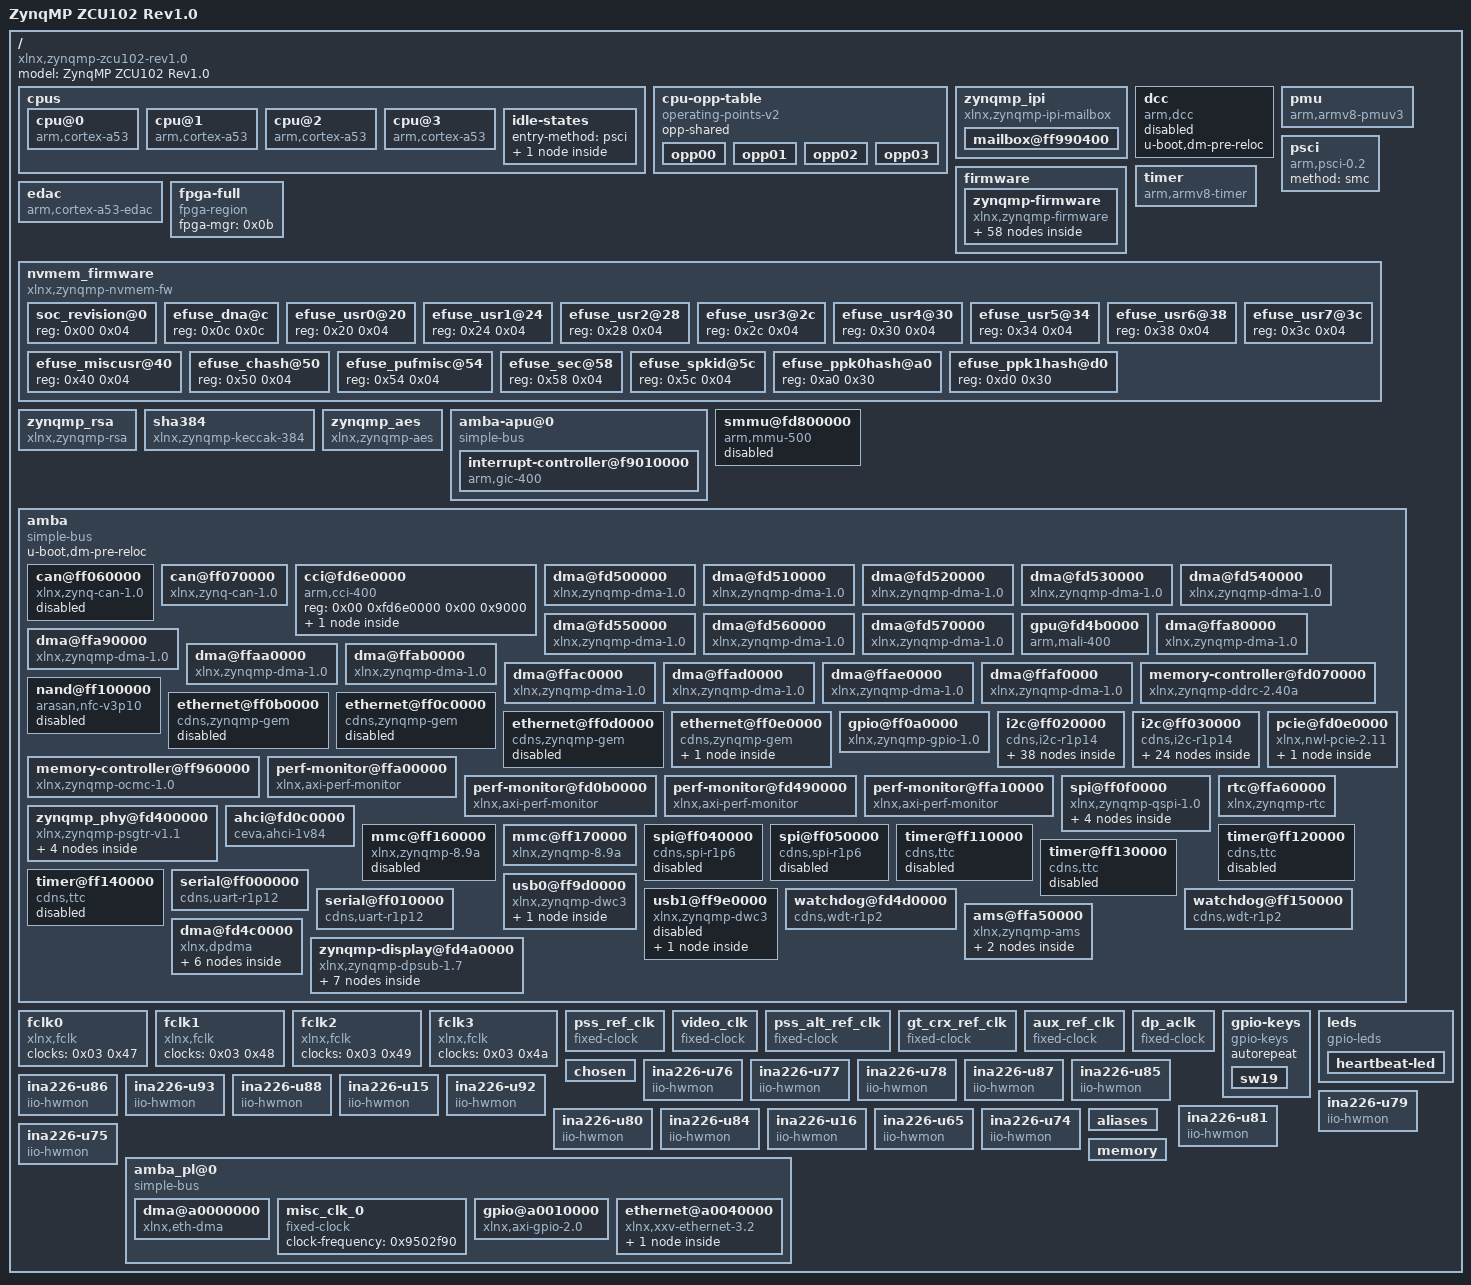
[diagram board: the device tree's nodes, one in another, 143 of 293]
/dts-v1/;

/ {
	compatible = "xlnx,zynqmp-zcu102-rev1.0\0xlnx,zynqmp-zcu102\0xlnx,zynqmp";
	#address-cells = <0x02>;
	#size-cells = <0x02>;
	model = "ZynqMP ZCU102 Rev1.0";

	cpus {
		#address-cells = <0x01>;
		#size-cells = <0x00>;

		cpu@0 {
			compatible = "arm,cortex-a53";
			device_type = "cpu";
			enable-method = "psci";
			operating-points-v2 = <0x01>;
			reg = <0x00>;
			cpu-idle-states = <0x02>;
			clocks = <0x03 0x0a>;
			phandle = <0x3b>;
		};

		cpu@1 {
			compatible = "arm,cortex-a53";
			device_type = "cpu";
			enable-method = "psci";
			reg = <0x01>;
			operating-points-v2 = <0x01>;
			cpu-idle-states = <0x02>;
			phandle = <0x3c>;
		};

		cpu@2 {
			compatible = "arm,cortex-a53";
			device_type = "cpu";
			enable-method = "psci";
			reg = <0x02>;
			operating-points-v2 = <0x01>;
			cpu-idle-states = <0x02>;
			phandle = <0x3d>;
		};

		cpu@3 {
			compatible = "arm,cortex-a53";
			device_type = "cpu";
			enable-method = "psci";
			reg = <0x03>;
			operating-points-v2 = <0x01>;
			cpu-idle-states = <0x02>;
			phandle = <0x3e>;
		};

		idle-states {
			entry-method = "psci";

			cpu-sleep-0 {
				compatible = "arm,idle-state";
				arm,psci-suspend-param = <0x40000000>;
				local-timer-stop;
				entry-latency-us = <0x12c>;
				exit-latency-us = <0x258>;
				min-residency-us = <0x2710>;
				phandle = <0x02>;
			};
		};
	};

	cpu-opp-table {
		compatible = "operating-points-v2";
		opp-shared;
		phandle = <0x01>;

		opp00 {
			opp-hz = <0x00 0x47868bf4>;
			opp-microvolt = <0xf4240>;
			clock-latency-ns = <0x7a120>;
		};

		opp01 {
			opp-hz = <0x00 0x23c345fa>;
			opp-microvolt = <0xf4240>;
			clock-latency-ns = <0x7a120>;
		};

		opp02 {
			opp-hz = <0x00 0x17d783fc>;
			opp-microvolt = <0xf4240>;
			clock-latency-ns = <0x7a120>;
		};

		opp03 {
			opp-hz = <0x00 0x11e1a2fd>;
			opp-microvolt = <0xf4240>;
			clock-latency-ns = <0x7a120>;
		};
	};

	zynqmp_ipi {
		u-boot,dm-pre-reloc;
		compatible = "xlnx,zynqmp-ipi-mailbox";
		interrupt-parent = <0x04>;
		interrupts = <0x00 0x23 0x04>;
		xlnx,ipi-id = <0x00>;
		#address-cells = <0x02>;
		#size-cells = <0x02>;
		ranges;

		mailbox@ff990400 {
			u-boot,dm-pre-reloc;
			reg = <0x00 0xff9905c0 0x00 0x20 0x00 0xff9905e0 0x00 0x20 0x00 0xff990e80 0x00 0x20 0x00 0xff990ea0 0x00 0x20>;
			reg-names = "local_request_region\0local_response_region\0remote_request_region\0remote_response_region";
			#mbox-cells = <0x01>;
			xlnx,ipi-id = <0x04>;
			phandle = <0x05>;
		};
	};

	dcc {
		compatible = "arm,dcc";
		status = "disabled";
		u-boot,dm-pre-reloc;
		phandle = <0x3f>;
	};

	pmu {
		compatible = "arm,armv8-pmuv3";
		interrupt-parent = <0x04>;
		interrupts = <0x00 0x8f 0x04 0x00 0x90 0x04 0x00 0x91 0x04 0x00 0x92 0x04>;
	};

	psci {
		compatible = "arm,psci-0.2";
		method = "smc";
	};

	firmware {

		zynqmp-firmware {
			compatible = "xlnx,zynqmp-firmware";
			u-boot,dm-pre-reloc;
			method = "smc";
			#power-domain-cells = <0x01>;
			phandle = <0x0c>;

			pcap {
				compatible = "xlnx,zynqmp-pcap-fpga";
				clock-names = "ref_clk";
				clocks = <0x03 0x29>;
				phandle = <0x0b>;
			};

			zynqmp-power {
				u-boot,dm-pre-reloc;
				compatible = "xlnx,zynqmp-power";
				interrupt-parent = <0x04>;
				interrupts = <0x00 0x23 0x04>;
				mboxes = <0x05 0x00 0x05 0x01>;
				mbox-names = "tx\0rx";
				phandle = <0x40>;
			};

			reset-controller {
				compatible = "xlnx,zynqmp-reset";
				#reset-cells = <0x01>;
				phandle = <0x1a>;
			};

			pinctrl {
				compatible = "xlnx,zynqmp-pinctrl";
				status = "okay";
				phandle = <0x41>;

				i2c0-default {
					phandle = <0x12>;

					mux {
						groups = "i2c0_3_grp";
						function = "i2c0";
					};

					conf {
						groups = "i2c0_3_grp";
						bias-pull-up;
						slew-rate = <0x01>;
						io-standard = <0x01>;
					};
				};

				i2c0-gpio {
					phandle = <0x13>;

					mux {
						groups = "gpio0_14_grp\0gpio0_15_grp";
						function = "gpio0";
					};

					conf {
						groups = "gpio0_14_grp\0gpio0_15_grp";
						slew-rate = <0x01>;
						io-standard = <0x01>;
					};
				};

				i2c1-default {
					phandle = <0x15>;

					mux {
						groups = "i2c1_4_grp";
						function = "i2c1";
					};

					conf {
						groups = "i2c1_4_grp";
						bias-pull-up;
						slew-rate = <0x01>;
						io-standard = <0x01>;
					};
				};

				i2c1-gpio {
					phandle = <0x16>;

					mux {
						groups = "gpio0_16_grp\0gpio0_17_grp";
						function = "gpio0";
					};

					conf {
						groups = "gpio0_16_grp\0gpio0_17_grp";
						slew-rate = <0x01>;
						io-standard = <0x01>;
					};
				};

				uart0-default {
					phandle = <0x1d>;

					mux {
						groups = "uart0_4_grp";
						function = "uart0";
					};

					conf {
						groups = "uart0_4_grp";
						slew-rate = <0x01>;
						io-standard = <0x01>;
					};

					conf-rx {
						pins = "MIO18";
						bias-high-impedance;
					};

					conf-tx {
						pins = "MIO19";
						bias-disable;
					};
				};

				uart1-default {
					phandle = <0x1e>;

					mux {
						groups = "uart1_5_grp";
						function = "uart1";
					};

					conf {
						groups = "uart1_5_grp";
						slew-rate = <0x01>;
						io-standard = <0x01>;
					};

					conf-rx {
						pins = "MIO21";
						bias-high-impedance;
					};

					conf-tx {
						pins = "MIO20";
						bias-disable;
					};
				};

				usb0-default {
					phandle = <0x1f>;

					mux {
						groups = "usb0_0_grp";
						function = "usb0";
					};

					conf {
						groups = "usb0_0_grp";
						slew-rate = <0x01>;
						io-standard = <0x01>;
					};

					conf-rx {
						pins = "MIO52\0MIO53\0MIO55";
						bias-high-impedance;
					};

					conf-tx {
						pins = "MIO54\0MIO56\0MIO57\0MIO58\0MIO59\0MIO60\0MIO61\0MIO62\0MIO63";
						bias-disable;
					};
				};

				gem3-default {
					phandle = <0x10>;

					mux {
						function = "ethernet3";
						groups = "ethernet3_0_grp";
					};

					conf {
						groups = "ethernet3_0_grp";
						slew-rate = <0x01>;
						io-standard = <0x01>;
					};

					conf-rx {
						pins = "MIO70\0MIO71\0MIO72\0MIO73\0MIO74\0MIO75";
						bias-high-impedance;
						low-power-disable;
					};

					conf-tx {
						pins = "MIO64\0MIO65\0MIO66\0MIO67\0MIO68\0MIO69";
						bias-disable;
						low-power-enable;
					};

					mux-mdio {
						function = "mdio3";
						groups = "mdio3_0_grp";
					};

					conf-mdio {
						groups = "mdio3_0_grp";
						slew-rate = <0x01>;
						io-standard = <0x01>;
						bias-disable;
					};
				};

				can1-default {
					phandle = <0x0d>;

					mux {
						function = "can1";
						groups = "can1_6_grp";
					};

					conf {
						groups = "can1_6_grp";
						slew-rate = <0x01>;
						io-standard = <0x01>;
					};

					conf-rx {
						pins = "MIO25";
						bias-high-impedance;
					};

					conf-tx {
						pins = "MIO24";
						bias-disable;
					};
				};

				sdhci1-default {
					phandle = <0x1c>;

					mux {
						groups = "sdio1_0_grp";
						function = "sdio1";
					};

					conf {
						groups = "sdio1_0_grp";
						slew-rate = <0x01>;
						io-standard = <0x01>;
						bias-disable;
					};

					mux-cd {
						groups = "sdio1_cd_0_grp";
						function = "sdio1_cd";
					};

					conf-cd {
						groups = "sdio1_cd_0_grp";
						bias-high-impedance;
						bias-pull-up;
						slew-rate = <0x01>;
						io-standard = <0x01>;
					};

					mux-wp {
						groups = "sdio1_wp_0_grp";
						function = "sdio1_wp";
					};

					conf-wp {
						groups = "sdio1_wp_0_grp";
						bias-high-impedance;
						bias-pull-up;
						slew-rate = <0x01>;
						io-standard = <0x01>;
					};
				};

				gpio-default {
					phandle = <0x11>;

					mux-sw {
						function = "gpio0";
						groups = "gpio0_22_grp\0gpio0_23_grp";
					};

					conf-sw {
						groups = "gpio0_22_grp\0gpio0_23_grp";
						slew-rate = <0x01>;
						io-standard = <0x01>;
					};

					mux-msp {
						function = "gpio0";
						groups = "gpio0_13_grp\0gpio0_38_grp";
					};

					conf-msp {
						groups = "gpio0_13_grp\0gpio0_38_grp";
						slew-rate = <0x01>;
						io-standard = <0x01>;
					};

					conf-pull-up {
						pins = "MIO22\0MIO23";
						bias-pull-up;
					};

					conf-pull-none {
						pins = "MIO13\0MIO38";
						bias-disable;
					};
				};
			};

			clock-controller {
				u-boot,dm-pre-reloc;
				#clock-cells = <0x01>;
				compatible = "xlnx,zynqmp-clk";
				clocks = <0x06 0x07 0x08 0x09 0x0a>;
				clock-names = "pss_ref_clk\0video_clk\0pss_alt_ref_clk\0aux_ref_clk\0gt_crx_ref_clk";
				phandle = <0x03>;
			};
		};
	};

	timer {
		compatible = "arm,armv8-timer";
		interrupt-parent = <0x04>;
		interrupts = <0x01 0x0d 0xf08 0x01 0x0e 0xf08 0x01 0x0b 0xf08 0x01 0x0a 0xf08>;
	};

	edac {
		compatible = "arm,cortex-a53-edac";
	};

	fpga-full {
		compatible = "fpga-region";
		fpga-mgr = <0x0b>;
		#address-cells = <0x02>;
		#size-cells = <0x02>;
		ranges;
		phandle = <0x42>;
	};

	nvmem_firmware {
		compatible = "xlnx,zynqmp-nvmem-fw";
		#address-cells = <0x01>;
		#size-cells = <0x01>;

		soc_revision@0 {
			reg = <0x00 0x04>;
			phandle = <0x19>;
		};

		efuse_dna@c {
			reg = <0x0c 0x0c>;
			phandle = <0x43>;
		};

		efuse_usr0@20 {
			reg = <0x20 0x04>;
			phandle = <0x44>;
		};

		efuse_usr1@24 {
			reg = <0x24 0x04>;
			phandle = <0x45>;
		};

		efuse_usr2@28 {
			reg = <0x28 0x04>;
			phandle = <0x46>;
		};

		efuse_usr3@2c {
			reg = <0x2c 0x04>;
			phandle = <0x47>;
		};

		efuse_usr4@30 {
			reg = <0x30 0x04>;
			phandle = <0x48>;
		};

		efuse_usr5@34 {
			reg = <0x34 0x04>;
			phandle = <0x49>;
		};

		efuse_usr6@38 {
			reg = <0x38 0x04>;
			phandle = <0x4a>;
		};

		efuse_usr7@3c {
			reg = <0x3c 0x04>;
			phandle = <0x4b>;
		};

		efuse_miscusr@40 {
			reg = <0x40 0x04>;
			phandle = <0x4c>;
		};

		efuse_chash@50 {
			reg = <0x50 0x04>;
			phandle = <0x4d>;
		};

		efuse_pufmisc@54 {
			reg = <0x54 0x04>;
			phandle = <0x4e>;
		};

		efuse_sec@58 {
			reg = <0x58 0x04>;
			phandle = <0x4f>;
		};

		efuse_spkid@5c {
			reg = <0x5c 0x04>;
			phandle = <0x50>;
		};

		efuse_ppk0hash@a0 {
			reg = <0xa0 0x30>;
			phandle = <0x51>;
		};

		efuse_ppk1hash@d0 {
			reg = <0xd0 0x30>;
			phandle = <0x52>;
		};
	};

	zynqmp_rsa {
		compatible = "xlnx,zynqmp-rsa";
		phandle = <0x53>;
	};

	sha384 {
		compatible = "xlnx,zynqmp-keccak-384";
		phandle = <0x54>;
	};

	zynqmp_aes {
		compatible = "xlnx,zynqmp-aes";
		phandle = <0x55>;
	};

	amba-apu@0 {
		compatible = "simple-bus";
		#address-cells = <0x02>;
		#size-cells = <0x01>;
		ranges = <0x00 0x00 0x00 0x00 0xffffffff>;
		phandle = <0x56>;

		interrupt-controller@f9010000 {
			compatible = "arm,gic-400";
			#interrupt-cells = <0x03>;
			reg = <0x00 0xf9010000 0x10000 0x00 0xf9020000 0x20000 0x00 0xf9040000 0x20000 0x00 0xf9060000 0x20000>;
			interrupt-controller;
			interrupt-parent = <0x04>;
			interrupts = <0x01 0x09 0xf04>;
			num_cpus = <0x02>;
			num_interrupts = <0x60>;
			phandle = <0x04>;
		};
	};

	smmu@fd800000 {
		compatible = "arm,mmu-500";
		reg = <0x00 0xfd800000 0x00 0x20000>;
		#iommu-cells = <0x01>;
		status = "disabled";
		#global-interrupts = <0x01>;
		interrupt-parent = <0x04>;
		interrupts = <0x00 0x9b 0x04 0x00 0x9b 0x04 0x00 0x9b 0x04 0x00 0x9b 0x04 0x00 0x9b 0x04 0x00 0x9b 0x04 0x00 0x9b 0x04 0x00 0x9b 0x04 0x00 0x9b 0x04 0x00 0x9b 0x04 0x00 0x9b 0x04 0x00 0x9b 0x04 0x00 0x9b 0x04 0x00 0x9b 0x04 0x00 0x9b 0x04 0x00 0x9b 0x04 0x00 0x9b 0x04>;
		phandle = <0x0e>;
	};

	amba {
		compatible = "simple-bus";
		u-boot,dm-pre-reloc;
		#address-cells = <0x02>;
		#size-cells = <0x02>;
		ranges;
		phandle = <0x57>;

		can@ff060000 {
			compatible = "xlnx,zynq-can-1.0";
			status = "disabled";
			clock-names = "can_clk\0pclk";
			reg = <0x00 0xff060000 0x00 0x1000>;
			interrupts = <0x00 0x17 0x04>;
			interrupt-parent = <0x04>;
			tx-fifo-depth = <0x40>;
			rx-fifo-depth = <0x40>;
			power-domains = <0x0c 0x2f>;
			clocks = <0x03 0x3f 0x03 0x1f>;
			phandle = <0x58>;
		};

		can@ff070000 {
			compatible = "xlnx,zynq-can-1.0";
			status = "okay";
			clock-names = "can_clk\0pclk";
			reg = <0x00 0xff070000 0x00 0x1000>;
			interrupts = <0x00 0x18 0x04>;
			interrupt-parent = <0x04>;
			tx-fifo-depth = <0x40>;
			rx-fifo-depth = <0x40>;
			power-domains = <0x0c 0x30>;
			clocks = <0x03 0x40 0x03 0x1f>;
			pinctrl-names = "default";
			pinctrl-0 = <0x0d>;
			phandle = <0x59>;
		};

		cci@fd6e0000 {
			compatible = "arm,cci-400";
			reg = <0x00 0xfd6e0000 0x00 0x9000>;
			ranges = <0x00 0x00 0xfd6e0000 0x10000>;
			#address-cells = <0x01>;
			#size-cells = <0x01>;
			phandle = <0x5a>;

			pmu@9000 {
				compatible = "arm,cci-400-pmu,r1";
				reg = <0x9000 0x5000>;
				interrupt-parent = <0x04>;
				interrupts = <0x00 0x7b 0x04 0x00 0x7b 0x04 0x00 0x7b 0x04 0x00 0x7b 0x04 0x00 0x7b 0x04>;
			};
		};

		dma@fd500000 {
			status = "okay";
			compatible = "xlnx,zynqmp-dma-1.0";
			reg = <0x00 0xfd500000 0x00 0x1000>;
			interrupt-parent = <0x04>;
			interrupts = <0x00 0x7c 0x04>;
			clock-names = "clk_main\0clk_apb";
			xlnx,bus-width = <0x80>;
			#stream-id-cells = <0x01>;
			iommus = <0x0e 0x14e8>;
			power-domains = <0x0c 0x2a>;
			clocks = <0x03 0x13 0x03 0x1f>;
			phandle = <0x5b>;
		};

		dma@fd510000 {
			status = "okay";
			compatible = "xlnx,zynqmp-dma-1.0";
			reg = <0x00 0xfd510000 0x00 0x1000>;
			interrupt-parent = <0x04>;
			interrupts = <0x00 0x7d 0x04>;
			clock-names = "clk_main\0clk_apb";
			xlnx,bus-width = <0x80>;
			#stream-id-cells = <0x01>;
			iommus = <0x0e 0x14e9>;
			power-domains = <0x0c 0x2a>;
			clocks = <0x03 0x13 0x03 0x1f>;
			phandle = <0x5c>;
		};

		dma@fd520000 {
			status = "okay";
			compatible = "xlnx,zynqmp-dma-1.0";
			reg = <0x00 0xfd520000 0x00 0x1000>;
			interrupt-parent = <0x04>;
			interrupts = <0x00 0x7e 0x04>;
			clock-names = "clk_main\0clk_apb";
			xlnx,bus-width = <0x80>;
			#stream-id-cells = <0x01>;
			iommus = <0x0e 0x14ea>;
			power-domains = <0x0c 0x2a>;
			clocks = <0x03 0x13 0x03 0x1f>;
			phandle = <0x5d>;
		};

		dma@fd530000 {
			status = "okay";
			compatible = "xlnx,zynqmp-dma-1.0";
			reg = <0x00 0xfd530000 0x00 0x1000>;
			interrupt-parent = <0x04>;
			interrupts = <0x00 0x7f 0x04>;
			clock-names = "clk_main\0clk_apb";
			xlnx,bus-width = <0x80>;
			#stream-id-cells = <0x01>;
			iommus = <0x0e 0x14eb>;
			power-domains = <0x0c 0x2a>;
			clocks = <0x03 0x13 0x03 0x1f>;
			phandle = <0x5e>;
		};

		dma@fd540000 {
			status = "okay";
			compatible = "xlnx,zynqmp-dma-1.0";
			reg = <0x00 0xfd540000 0x00 0x1000>;
			interrupt-parent = <0x04>;
			interrupts = <0x00 0x80 0x04>;
			clock-names = "clk_main\0clk_apb";
			xlnx,bus-width = <0x80>;
			#stream-id-cells = <0x01>;
			iommus = <0x0e 0x14ec>;
			power-domains = <0x0c 0x2a>;
			clocks = <0x03 0x13 0x03 0x1f>;
			phandle = <0x5f>;
		};

		dma@fd550000 {
			status = "okay";
			compatible = "xlnx,zynqmp-dma-1.0";
			reg = <0x00 0xfd550000 0x00 0x1000>;
			interrupt-parent = <0x04>;
			interrupts = <0x00 0x81 0x04>;
			clock-names = "clk_main\0clk_apb";
			xlnx,bus-width = <0x80>;
			#stream-id-cells = <0x01>;
			iommus = <0x0e 0x14ed>;
			power-domains = <0x0c 0x2a>;
			clocks = <0x03 0x13 0x03 0x1f>;
			phandle = <0x60>;
		};

		dma@fd560000 {
			status = "okay";
			compatible = "xlnx,zynqmp-dma-1.0";
			reg = <0x00 0xfd560000 0x00 0x1000>;
			interrupt-parent = <0x04>;
			interrupts = <0x00 0x82 0x04>;
			clock-names = "clk_main\0clk_apb";
			xlnx,bus-width = <0x80>;
			#stream-id-cells = <0x01>;
			iommus = <0x0e 0x14ee>;
			power-domains = <0x0c 0x2a>;
			clocks = <0x03 0x13 0x03 0x1f>;
			phandle = <0x61>;
		};

		dma@fd570000 {
			status = "okay";
			compatible = "xlnx,zynqmp-dma-1.0";
			reg = <0x00 0xfd570000 0x00 0x1000>;
			interrupt-parent = <0x04>;
			interrupts = <0x00 0x83 0x04>;
			clock-names = "clk_main\0clk_apb";
			xlnx,bus-width = <0x80>;
			#stream-id-cells = <0x01>;
			iommus = <0x0e 0x14ef>;
			power-domains = <0x0c 0x2a>;
			clocks = <0x03 0x13 0x03 0x1f>;
			phandle = <0x62>;
		};

		gpu@fd4b0000 {
			status = "okay";
			compatible = "arm,mali-400\0arm,mali-utgard";
			reg = <0x00 0xfd4b0000 0x00 0x10000>;
			interrupt-parent = <0x04>;
			interrupts = <0x00 0x84 0x04 0x00 0x84 0x04 0x00 0x84 0x04 0x00 0x84 0x04 0x00 0x84 0x04 0x00 0x84 0x04>;
			interrupt-names = "IRQGP\0IRQGPMMU\0IRQPP0\0IRQPPMMU0\0IRQPP1\0IRQPPMMU1";
			clock-names = "gpu\0gpu_pp0\0gpu_pp1";
			power-domains = <0x0c 0x3a>;
			clocks = <0x03 0x18 0x03 0x19 0x03 0x1a>;
			xlnx,tz-nonsecure = <0x01>;
			phandle = <0x63>;
		};

		dma@ffa80000 {
			status = "okay";
			compatible = "xlnx,zynqmp-dma-1.0";
			reg = <0x00 0xffa80000 0x00 0x1000>;
			interrupt-parent = <0x04>;
			interrupts = <0x00 0x4d 0x04>;
			clock-names = "clk_main\0clk_apb";
			xlnx,bus-width = <0x40>;
			#stream-id-cells = <0x01>;
			power-domains = <0x0c 0x2b>;
			clocks = <0x03 0x44 0x03 0x1f>;
			phandle = <0x64>;
		};

		dma@ffa90000 {
			status = "okay";
			compatible = "xlnx,zynqmp-dma-1.0";
			reg = <0x00 0xffa90000 0x00 0x1000>;
			interrupt-parent = <0x04>;
			interrupts = <0x00 0x4e 0x04>;
			clock-names = "clk_main\0clk_apb";
			xlnx,bus-width = <0x40>;
			#stream-id-cells = <0x01>;
			power-domains = <0x0c 0x2b>;
			clocks = <0x03 0x44 0x03 0x1f>;
			phandle = <0x65>;
		};

		dma@ffaa0000 {
			status = "okay";
			compatible = "xlnx,zynqmp-dma-1.0";
			reg = <0x00 0xffaa0000 0x00 0x1000>;
			interrupt-parent = <0x04>;
			interrupts = <0x00 0x4f 0x04>;
			clock-names = "clk_main\0clk_apb";
			xlnx,bus-width = <0x40>;
			#stream-id-cells = <0x01>;
			power-domains = <0x0c 0x2b>;
			clocks = <0x03 0x44 0x03 0x1f>;
			phandle = <0x66>;
		};

		dma@ffab0000 {
			status = "okay";
			compatible = "xlnx,zynqmp-dma-1.0";
			reg = <0x00 0xffab0000 0x00 0x1000>;
			interrupt-parent = <0x04>;
			interrupts = <0x00 0x50 0x04>;
			clock-names = "clk_main\0clk_apb";
			xlnx,bus-width = <0x40>;
			#stream-id-cells = <0x01>;
			power-domains = <0x0c 0x2b>;
			clocks = <0x03 0x44 0x03 0x1f>;
			phandle = <0x67>;
		};

		dma@ffac0000 {
			status = "okay";
			compatible = "xlnx,zynqmp-dma-1.0";
			reg = <0x00 0xffac0000 0x00 0x1000>;
			interrupt-parent = <0x04>;
			interrupts = <0x00 0x51 0x04>;
			clock-names = "clk_main\0clk_apb";
			xlnx,bus-width = <0x40>;
			#stream-id-cells = <0x01>;
			power-domains = <0x0c 0x2b>;
			clocks = <0x03 0x44 0x03 0x1f>;
			phandle = <0x68>;
		};

		dma@ffad0000 {
			status = "okay";
			compatible = "xlnx,zynqmp-dma-1.0";
			reg = <0x00 0xffad0000 0x00 0x1000>;
			interrupt-parent = <0x04>;
			interrupts = <0x00 0x52 0x04>;
			clock-names = "clk_main\0clk_apb";
			xlnx,bus-width = <0x40>;
			#stream-id-cells = <0x01>;
			power-domains = <0x0c 0x2b>;
			clocks = <0x03 0x44 0x03 0x1f>;
			phandle = <0x69>;
		};

		dma@ffae0000 {
			status = "okay";
			compatible = "xlnx,zynqmp-dma-1.0";
			reg = <0x00 0xffae0000 0x00 0x1000>;
			interrupt-parent = <0x04>;
			interrupts = <0x00 0x53 0x04>;
			clock-names = "clk_main\0clk_apb";
			xlnx,bus-width = <0x40>;
			#stream-id-cells = <0x01>;
			power-domains = <0x0c 0x2b>;
			clocks = <0x03 0x44 0x03 0x1f>;
			phandle = <0x6a>;
		};

		dma@ffaf0000 {
			status = "okay";
			compatible = "xlnx,zynqmp-dma-1.0";
			reg = <0x00 0xffaf0000 0x00 0x1000>;
			interrupt-parent = <0x04>;
			interrupts = <0x00 0x54 0x04>;
			clock-names = "clk_main\0clk_apb";
			xlnx,bus-width = <0x40>;
			#stream-id-cells = <0x01>;
			power-domains = <0x0c 0x2b>;
			clocks = <0x03 0x44 0x03 0x1f>;
			phandle = <0x6b>;
		};

		memory-controller@fd070000 {
			compatible = "xlnx,zynqmp-ddrc-2.40a";
			reg = <0x00 0xfd070000 0x00 0x30000>;
			interrupt-parent = <0x04>;
			interrupts = <0x00 0x70 0x04>;
			phandle = <0x6c>;
		};

		nand@ff100000 {
			compatible = "arasan,nfc-v3p10";
			status = "disabled";
			reg = <0x00 0xff100000 0x00 0x1000>;
			clock-names = "clk_sys\0clk_flash";
			interrupt-parent = <0x04>;
			interrupts = <0x00 0x0e 0x04>;
			#address-cells = <0x01>;
			#size-cells = <0x00>;
			#stream-id-cells = <0x01>;
			iommus = <0x0e 0x872>;
			power-domains = <0x0c 0x2c>;
			clocks = <0x03 0x3c 0x03 0x1f>;
			phandle = <0x6d>;
		};

		ethernet@ff0b0000 {
			compatible = "cdns,zynqmp-gem\0cdns,gem";
			status = "disabled";
			interrupt-parent = <0x04>;
			interrupts = <0x00 0x39 0x04 0x00 0x39 0x04>;
			reg = <0x00 0xff0b0000 0x00 0x1000>;
			clock-names = "pclk\0hclk\0tx_clk\0rx_clk\0tsu_clk";
			#address-cells = <0x01>;
			#size-cells = <0x00>;
			#stream-id-cells = <0x01>;
			iommus = <0x0e 0x874>;
			power-domains = <0x0c 0x1d>;
			clocks = <0x03 0x1f 0x03 0x68 0x03 0x2d 0x03 0x31 0x03 0x2c>;
			phandle = <0x6e>;
		};

		ethernet@ff0c0000 {
			compatible = "cdns,zynqmp-gem\0cdns,gem";
			status = "disabled";
			interrupt-parent = <0x04>;
			interrupts = <0x00 0x3b 0x04 0x00 0x3b 0x04>;
			reg = <0x00 0xff0c0000 0x00 0x1000>;
			clock-names = "pclk\0hclk\0tx_clk\0rx_clk\0tsu_clk";
			#address-cells = <0x01>;
			#size-cells = <0x00>;
			#stream-id-cells = <0x01>;
			iommus = <0x0e 0x875>;
			power-domains = <0x0c 0x1e>;
			clocks = <0x03 0x1f 0x03 0x69 0x03 0x2e 0x03 0x32 0x03 0x2c>;
			phandle = <0x6f>;
		};

		ethernet@ff0d0000 {
			compatible = "cdns,zynqmp-gem\0cdns,gem";
			status = "disabled";
			interrupt-parent = <0x04>;
			interrupts = <0x00 0x3d 0x04 0x00 0x3d 0x04>;
			reg = <0x00 0xff0d0000 0x00 0x1000>;
			clock-names = "pclk\0hclk\0tx_clk\0rx_clk\0tsu_clk";
			#address-cells = <0x01>;
			#size-cells = <0x00>;
			#stream-id-cells = <0x01>;
			iommus = <0x0e 0x876>;
			power-domains = <0x0c 0x1f>;
			clocks = <0x03 0x1f 0x03 0x6a 0x03 0x2f 0x03 0x33 0x03 0x2c>;
			phandle = <0x70>;
		};

		ethernet@ff0e0000 {
			compatible = "cdns,zynqmp-gem\0cdns,gem";
			status = "okay";
			interrupt-parent = <0x04>;
			interrupts = <0x00 0x3f 0x04 0x00 0x3f 0x04>;
			reg = <0x00 0xff0e0000 0x00 0x1000>;
			clock-names = "pclk\0hclk\0tx_clk\0rx_clk\0tsu_clk";
			#address-cells = <0x01>;
			#size-cells = <0x00>;
			#stream-id-cells = <0x01>;
			iommus = <0x0e 0x877>;
			power-domains = <0x0c 0x20>;
			clocks = <0x03 0x1f 0x03 0x6b 0x03 0x30 0x03 0x34 0x03 0x2c>;
			phy-handle = <0x0f>;
			pinctrl-names = "default";
			pinctrl-0 = <0x10>;
			phy-mode = "rgmii-id";
			xlnx,ptp-enet-clock = <0x00>;
			local-mac-address = [00 0a 35 00 22 01];
			phandle = <0x71>;

			ethernet-phy@c {
				reg = <0x0c>;
				ti,rx-internal-delay = <0x08>;
				ti,tx-internal-delay = <0x0a>;
				ti,fifo-depth = <0x01>;
				ti,dp83867-rxctrl-strap-quirk;
				phandle = <0x0f>;
			};
		};

		gpio@ff0a0000 {
			compatible = "xlnx,zynqmp-gpio-1.0";
			status = "okay";
			#gpio-cells = <0x02>;
			gpio-controller;
			interrupt-parent = <0x04>;
			interrupts = <0x00 0x10 0x04>;
			interrupt-controller;
			#interrupt-cells = <0x02>;
			reg = <0x00 0xff0a0000 0x00 0x1000>;
			power-domains = <0x0c 0x2e>;
			clocks = <0x03 0x1f>;
			pinctrl-names = "default";
			pinctrl-0 = <0x11>;
			emio-gpio-width = <0x20>;
			gpio-mask-high = <0x00>;
			gpio-mask-low = <0x5600>;
			phandle = <0x14>;
		};

		i2c@ff020000 {
			compatible = "cdns,i2c-r1p14\0cdns,i2c-r1p10";
			status = "okay";
			interrupt-parent = <0x04>;
			interrupts = <0x00 0x11 0x04>;
			reg = <0x00 0xff020000 0x00 0x1000>;
			#address-cells = <0x01>;
			#size-cells = <0x00>;
			power-domains = <0x0c 0x25>;
			clocks = <0x03 0x3d>;
			pinctrl-names = "default\0gpio";
			pinctrl-0 = <0x12>;
			pinctrl-1 = <0x13>;
			scl-gpios = <0x14 0x0e 0x00>;
			sda-gpios = <0x14 0x0f 0x00>;
			clock-frequency = <0x61a80>;
			phandle = <0x72>;

			gpio@20 {
				compatible = "ti,tca6416";
				reg = <0x20>;
				gpio-controller;
				#gpio-cells = <0x02>;
				gpio-line-names = "PS_GTR_LAN_SEL0\0PS_GTR_LAN_SEL1\0PS_GTR_LAN_SEL2\0PS_GTR_LAN_SEL3\0PCI_CLK_DIR_SEL\0IIC_MUX_RESET_B\0GEM3_EXP_RESET_B\0\0\0\0\0\0\0\0\0";
				phandle = <0x73>;
			};

			gpio@21 {
				compatible = "ti,tca6416";
				reg = <0x21>;
				gpio-controller;
				#gpio-cells = <0x02>;
				gpio-line-names = "VCCPSPLL_EN\0MGTRAVCC_EN\0MGTRAVTT_EN\0VCCPSDDRPLL_EN\0MIO26_PMU_INPUT_LS\0PL_PMBUS_ALERT\0PS_PMBUS_ALERT\0MAXIM_PMBUS_ALERT\0PL_DDR4_VTERM_EN\0PL_DDR4_VPP_2V5_EN\0PS_DIMM_VDDQ_TO_PSVCCO_ON\0PS_DIMM_SUSPEND_EN\0PS_DDR4_VTERM_EN\0PS_DDR4_VPP_2V5_EN\0\0";
				phandle = <0x74>;
			};

			i2c-mux@75 {
				compatible = "nxp,pca9544";
				#address-cells = <0x01>;
				#size-cells = <0x00>;
				reg = <0x75>;

				i2c@0 {
					#address-cells = <0x01>;
					#size-cells = <0x00>;
					reg = <0x00>;

					ina226@40 {
						compatible = "ti,ina226";
						#io-channel-cells = <0x01>;
						label = "ina226-u76";
						reg = <0x40>;
						shunt-resistor = <0x1388>;
						phandle = <0x27>;
					};

					ina226@41 {
						compatible = "ti,ina226";
						#io-channel-cells = <0x01>;
						label = "ina226-u77";
						reg = <0x41>;
						shunt-resistor = <0x1388>;
						phandle = <0x28>;
					};

					ina226@42 {
						compatible = "ti,ina226";
						#io-channel-cells = <0x01>;
						label = "ina226-u78";
						reg = <0x42>;
						shunt-resistor = <0x1388>;
						phandle = <0x29>;
					};

					ina226@43 {
						compatible = "ti,ina226";
						#io-channel-cells = <0x01>;
						label = "ina226-u87";
						reg = <0x43>;
						shunt-resistor = <0x1388>;
						phandle = <0x2a>;
					};

					ina226@44 {
						compatible = "ti,ina226";
						#io-channel-cells = <0x01>;
						label = "ina226-u85";
						reg = <0x44>;
						shunt-resistor = <0x1388>;
						phandle = <0x2b>;
					};

					ina226@45 {
						compatible = "ti,ina226";
						#io-channel-cells = <0x01>;
						label = "ina226-u86";
						reg = <0x45>;
						shunt-resistor = <0x1388>;
						phandle = <0x2c>;
					};

					ina226@46 {
						compatible = "ti,ina226";
						#io-channel-cells = <0x01>;
						label = "ina226-u93";
						reg = <0x46>;
						shunt-resistor = <0x1388>;
						phandle = <0x2d>;
					};

					ina226@47 {
						compatible = "ti,ina226";
						#io-channel-cells = <0x01>;
						label = "ina226-u88";
						reg = <0x47>;
						shunt-resistor = <0x1388>;
						phandle = <0x2e>;
					};

					ina226@4a {
						compatible = "ti,ina226";
						#io-channel-cells = <0x01>;
						label = "ina226-u15";
						reg = <0x4a>;
						shunt-resistor = <0x1388>;
						phandle = <0x2f>;
					};

					ina226@4b {
						compatible = "ti,ina226";
						#io-channel-cells = <0x01>;
						label = "ina226-u92";
						reg = <0x4b>;
						shunt-resistor = <0x1388>;
						phandle = <0x30>;
					};
				};

				i2c@1 {
					#address-cells = <0x01>;
					#size-cells = <0x00>;
					reg = <0x01>;

					ina226@40 {
						compatible = "ti,ina226";
						#io-channel-cells = <0x01>;
						label = "ina226-u79";
						reg = <0x40>;
						shunt-resistor = <0x7d0>;
						phandle = <0x31>;
					};

					ina226@41 {
						compatible = "ti,ina226";
						#io-channel-cells = <0x01>;
						label = "ina226-u81";
						reg = <0x41>;
						shunt-resistor = <0x1388>;
						phandle = <0x32>;
					};

					ina226@42 {
						compatible = "ti,ina226";
						#io-channel-cells = <0x01>;
						label = "ina226-u80";
						reg = <0x42>;
						shunt-resistor = <0x1388>;
						phandle = <0x33>;
					};

					ina226@43 {
						compatible = "ti,ina226";
						#io-channel-cells = <0x01>;
						label = "ina226-u84";
						reg = <0x43>;
						shunt-resistor = <0x1388>;
						phandle = <0x34>;
					};

					ina226@44 {
						compatible = "ti,ina226";
						#io-channel-cells = <0x01>;
						label = "ina226-u16";
						reg = <0x44>;
						shunt-resistor = <0x1388>;
						phandle = <0x35>;
					};

					ina226@45 {
						compatible = "ti,ina226";
						#io-channel-cells = <0x01>;
						label = "ina226-u65";
						reg = <0x45>;
						shunt-resistor = <0x1388>;
						phandle = <0x36>;
					};

					ina226@46 {
						compatible = "ti,ina226";
						#io-channel-cells = <0x01>;
						label = "ina226-u74";
						reg = <0x46>;
						shunt-resistor = <0x1388>;
						phandle = <0x37>;
					};

					ina226@47 {
						compatible = "ti,ina226";
						#io-channel-cells = <0x01>;
						label = "ina226-u75";
						reg = <0x47>;
						shunt-resistor = <0x1388>;
						phandle = <0x38>;
					};
				};

				i2c@2 {
					#address-cells = <0x01>;
					#size-cells = <0x00>;
					reg = <0x02>;

					max15301@a {
						compatible = "maxim,max15301";
						reg = <0x0a>;
					};

					max15303@b {
						compatible = "maxim,max15303";
						reg = <0x0b>;
					};

					max15303@10 {
						compatible = "maxim,max15303";
						reg = <0x10>;
					};

					max15301@13 {
						compatible = "maxim,max15301";
						reg = <0x13>;
					};

					max15303@14 {
						compatible = "maxim,max15303";
						reg = <0x14>;
					};

					max15303@15 {
						compatible = "maxim,max15303";
						reg = <0x15>;
					};

					max15303@16 {
						compatible = "maxim,max15303";
						reg = <0x16>;
					};

					max15303@17 {
						compatible = "maxim,max15303";
						reg = <0x17>;
					};

					max15301@18 {
						compatible = "maxim,max15301";
						reg = <0x18>;
					};

					max15303@1a {
						compatible = "maxim,max15303";
						reg = <0x1a>;
					};

					max15303@1b {
						compatible = "maxim,max15303";
						reg = <0x1b>;
					};

					max15303@1d {
						compatible = "maxim,max15303";
						reg = <0x1d>;
					};

					max20751@72 {
						compatible = "maxim,max20751";
						reg = <0x72>;
					};

					max20751@73 {
						compatible = "maxim,max20751";
						reg = <0x73>;
					};
				};
			};
		};

		i2c@ff030000 {
			compatible = "cdns,i2c-r1p14\0cdns,i2c-r1p10";
			status = "okay";
			interrupt-parent = <0x04>;
			interrupts = <0x00 0x12 0x04>;
			reg = <0x00 0xff030000 0x00 0x1000>;
			#address-cells = <0x01>;
			#size-cells = <0x00>;
			power-domains = <0x0c 0x26>;
			clocks = <0x03 0x3e>;
			pinctrl-names = "default\0gpio";
			pinctrl-0 = <0x15>;
			pinctrl-1 = <0x16>;
			scl-gpios = <0x14 0x10 0x00>;
			sda-gpios = <0x14 0x11 0x00>;
			clock-frequency = <0x61a80>;
			phandle = <0x75>;

			i2c-mux@74 {
				compatible = "nxp,pca9548";
				#address-cells = <0x01>;
				#size-cells = <0x00>;
				reg = <0x74>;

				i2c@0 {
					#address-cells = <0x01>;
					#size-cells = <0x00>;
					reg = <0x00>;

					eeprom@54 {
						compatible = "atmel,24c08";
						reg = <0x54>;
						#address-cells = <0x01>;
						#size-cells = <0x01>;
						phandle = <0x76>;

						board-sn@0 {
							reg = <0x00 0x14>;
							phandle = <0x77>;
						};

						eth-mac@20 {
							reg = <0x20 0x06>;
							phandle = <0x78>;
						};

						board-name@d0 {
							reg = <0xd0 0x06>;
							phandle = <0x79>;
						};

						board-revision@e0 {
							reg = <0xe0 0x03>;
							phandle = <0x7a>;
						};
					};
				};

				i2c@1 {
					#address-cells = <0x01>;
					#size-cells = <0x00>;
					reg = <0x01>;

					clock-generator@36 {
						compatible = "silabs,si5341";
						reg = <0x36>;
						phandle = <0x7b>;
					};
				};

				i2c@2 {
					#address-cells = <0x01>;
					#size-cells = <0x00>;
					reg = <0x02>;

					clock-generator@5d {
						#clock-cells = <0x00>;
						compatible = "silabs,si570";
						reg = <0x5d>;
						temperature-stability = <0x32>;
						factory-fout = <0x11e1a300>;
						clock-frequency = <0x11e1a300>;
						clock-output-names = "si570_user";
						phandle = <0x7c>;
					};
				};

				i2c@3 {
					#address-cells = <0x01>;
					#size-cells = <0x00>;
					reg = <0x03>;

					clock-generator@5d {
						#clock-cells = <0x00>;
						compatible = "silabs,si570";
						reg = <0x5d>;
						temperature-stability = <0x32>;
						factory-fout = <0x9502f90>;
						clock-frequency = <0x9502f90>;
						clock-output-names = "si570_mgt";
						phandle = <0x7d>;
					};
				};

				i2c@4 {
					#address-cells = <0x01>;
					#size-cells = <0x00>;
					reg = <0x04>;

					clock-generator@69 {
						compatible = "silabs,si5328";
						reg = <0x69>;
						phandle = <0x7e>;
					};
				};
			};

			i2c-mux@75 {
				compatible = "nxp,pca9548";
				#address-cells = <0x01>;
				#size-cells = <0x00>;
				reg = <0x75>;

				i2c@0 {
					#address-cells = <0x01>;
					#size-cells = <0x00>;
					reg = <0x00>;
				};

				i2c@1 {
					#address-cells = <0x01>;
					#size-cells = <0x00>;
					reg = <0x01>;
				};

				i2c@2 {
					#address-cells = <0x01>;
					#size-cells = <0x00>;
					reg = <0x02>;
				};

				i2c@3 {
					#address-cells = <0x01>;
					#size-cells = <0x00>;
					reg = <0x03>;
				};

				i2c@4 {
					#address-cells = <0x01>;
					#size-cells = <0x00>;
					reg = <0x04>;
				};

				i2c@5 {
					#address-cells = <0x01>;
					#size-cells = <0x00>;
					reg = <0x05>;
				};

				i2c@6 {
					#address-cells = <0x01>;
					#size-cells = <0x00>;
					reg = <0x06>;
				};

				i2c@7 {
					#address-cells = <0x01>;
					#size-cells = <0x00>;
					reg = <0x07>;
				};
			};
		};

		memory-controller@ff960000 {
			compatible = "xlnx,zynqmp-ocmc-1.0";
			reg = <0x00 0xff960000 0x00 0x1000>;
			interrupt-parent = <0x04>;
			interrupts = <0x00 0x0a 0x04>;
			phandle = <0x7f>;
		};

		perf-monitor@ffa00000 {
			compatible = "xlnx,axi-perf-monitor";
			reg = <0x00 0xffa00000 0x00 0x10000>;
			interrupts = <0x00 0x19 0x04>;
			interrupt-parent = <0x04>;
			xlnx,enable-profile = <0x00>;
			xlnx,enable-trace = <0x00>;
			xlnx,num-monitor-slots = <0x01>;
			xlnx,enable-event-count = <0x01>;
			xlnx,enable-event-log = <0x01>;
			xlnx,have-sampled-metric-cnt = <0x01>;
			xlnx,num-of-counters = <0x08>;
			xlnx,metric-count-width = <0x20>;
			xlnx,metrics-sample-count-width = <0x20>;
			xlnx,global-count-width = <0x20>;
			xlnx,metric-count-scale = <0x01>;
			clocks = <0x03 0x1f>;
			phandle = <0x80>;
		};

		perf-monitor@fd0b0000 {
			compatible = "xlnx,axi-perf-monitor";
			reg = <0x00 0xfd0b0000 0x00 0x10000>;
			interrupts = <0x00 0x7b 0x04>;
			interrupt-parent = <0x04>;
			xlnx,enable-profile = <0x00>;
			xlnx,enable-trace = <0x00>;
			xlnx,num-monitor-slots = <0x06>;
			xlnx,enable-event-count = <0x01>;
			xlnx,enable-event-log = <0x00>;
			xlnx,have-sampled-metric-cnt = <0x01>;
			xlnx,num-of-counters = <0x0a>;
			xlnx,metric-count-width = <0x20>;
			xlnx,metrics-sample-count-width = <0x20>;
			xlnx,global-count-width = <0x20>;
			xlnx,metric-count-scale = <0x01>;
			clocks = <0x03 0x1c>;
			phandle = <0x81>;
		};

		perf-monitor@fd490000 {
			compatible = "xlnx,axi-perf-monitor";
			reg = <0x00 0xfd490000 0x00 0x10000>;
			interrupts = <0x00 0x7b 0x04>;
			interrupt-parent = <0x04>;
			xlnx,enable-profile = <0x00>;
			xlnx,enable-trace = <0x00>;
			xlnx,num-monitor-slots = <0x01>;
			xlnx,enable-event-count = <0x01>;
			xlnx,enable-event-log = <0x00>;
			xlnx,have-sampled-metric-cnt = <0x01>;
			xlnx,num-of-counters = <0x08>;
			xlnx,metric-count-width = <0x20>;
			xlnx,metrics-sample-count-width = <0x20>;
			xlnx,global-count-width = <0x20>;
			xlnx,metric-count-scale = <0x01>;
			clocks = <0x03 0x1c>;
			phandle = <0x82>;
		};

		perf-monitor@ffa10000 {
			compatible = "xlnx,axi-perf-monitor";
			reg = <0x00 0xffa10000 0x00 0x10000>;
			interrupts = <0x00 0x19 0x04>;
			interrupt-parent = <0x04>;
			xlnx,enable-profile = <0x00>;
			xlnx,enable-trace = <0x00>;
			xlnx,num-monitor-slots = <0x01>;
			xlnx,enable-event-count = <0x01>;
			xlnx,enable-event-log = <0x01>;
			xlnx,have-sampled-metric-cnt = <0x01>;
			xlnx,num-of-counters = <0x08>;
			xlnx,metric-count-width = <0x20>;
			xlnx,metrics-sample-count-width = <0x20>;
			xlnx,global-count-width = <0x20>;
			xlnx,metric-count-scale = <0x01>;
			clocks = <0x03 0x1f>;
			phandle = <0x83>;
		};

		pcie@fd0e0000 {
			compatible = "xlnx,nwl-pcie-2.11";
			status = "okay";
			#address-cells = <0x03>;
			#size-cells = <0x02>;
			#interrupt-cells = <0x01>;
			msi-controller;
			device_type = "pci";
			interrupt-parent = <0x04>;
			interrupts = <0x00 0x76 0x04 0x00 0x75 0x04 0x00 0x74 0x04 0x00 0x73 0x04 0x00 0x72 0x04>;
			interrupt-names = "misc\0dummy\0intx\0msi1\0msi0";
			msi-parent = <0x17>;
			reg = <0x00 0xfd0e0000 0x00 0x1000 0x00 0xfd480000 0x00 0x1000 0x80 0x00 0x00 0x1000000>;
			reg-names = "breg\0pcireg\0cfg";
			ranges = <0x2000000 0x00 0xe0000000 0x00 0xe0000000 0x00 0x10000000 0x43000000 0x06 0x00 0x06 0x00 0x02 0x00>;
			interrupt-map-mask = <0x00 0x00 0x00 0x07>;
			bus-range = <0x00 0xff>;
			interrupt-map = <0x00 0x00 0x00 0x01 0x18 0x01 0x00 0x00 0x00 0x02 0x18 0x02 0x00 0x00 0x00 0x03 0x18 0x03 0x00 0x00 0x00 0x04 0x18 0x04>;
			power-domains = <0x0c 0x3b>;
			clocks = <0x03 0x17>;
			xlnx,bar0-enable = <0x00>;
			xlnx,bar1-enable = <0x00>;
			xlnx,bar2-enable = <0x00>;
			xlnx,bar3-enable = <0x00>;
			xlnx,bar4-enable = <0x00>;
			xlnx,bar5-enable = <0x00>;
			xlnx,pcie-mode = "Root Port";
			xlnx,tz-nonsecure = <0x00>;
			phandle = <0x17>;

			legacy-interrupt-controller {
				interrupt-controller;
				#address-cells = <0x00>;
				#interrupt-cells = <0x01>;
				phandle = <0x18>;
			};
		};

		spi@ff0f0000 {
			u-boot,dm-pre-reloc;
			compatible = "xlnx,zynqmp-qspi-1.0";
			status = "okay";
			clock-names = "ref_clk\0pclk";
			interrupts = <0x00 0x0f 0x04>;
			interrupt-parent = <0x04>;
			num-cs = <0x01>;
			reg = <0x00 0xff0f0000 0x00 0x1000 0x00 0xc0000000 0x00 0x8000000>;
			#address-cells = <0x01>;
			#size-cells = <0x00>;
			#stream-id-cells = <0x01>;
			iommus = <0x0e 0x873>;
			power-domains = <0x0c 0x2d>;
			clocks = <0x03 0x35 0x03 0x1f>;
			is-dual = <0x01>;
			spi-rx-bus-width = <0x04>;
			spi-tx-bus-width = <0x04>;
			phandle = <0x84>;

			flash@0 {
				compatible = "m25p80\0jedec,spi-nor";
				#address-cells = <0x01>;
				#size-cells = <0x01>;
				reg = <0x00>;
				spi-tx-bus-width = <0x01>;
				spi-rx-bus-width = <0x04>;
				spi-max-frequency = <0x66ff300>;
				phandle = <0x85>;

				partition@0 {
					label = "boot";
					reg = <0x00 0x100000>;
				};

				partition@1 {
					label = "bootenv";
					reg = <0x100000 0x40000>;
				};

				partition@2 {
					label = "kernel";
					reg = <0x140000 0x1600000>;
				};
			};
		};

		rtc@ffa60000 {
			compatible = "xlnx,zynqmp-rtc";
			status = "okay";
			reg = <0x00 0xffa60000 0x00 0x100>;
			interrupt-parent = <0x04>;
			interrupts = <0x00 0x1a 0x04 0x00 0x1b 0x04>;
			interrupt-names = "alarm\0sec";
			calibration = <0x8000>;
			phandle = <0x86>;
		};

		zynqmp_phy@fd400000 {
			compatible = "xlnx,zynqmp-psgtr-v1.1";
			status = "okay";
			reg = <0x00 0xfd400000 0x00 0x40000 0x00 0xfd3d0000 0x00 0x1000>;
			reg-names = "serdes\0siou";
			nvmem-cells = <0x19>;
			nvmem-cell-names = "soc_revision";
			resets = <0x1a 0x10 0x1a 0x3b 0x1a 0x3c 0x1a 0x3d 0x1a 0x3e 0x1a 0x3f 0x1a 0x40 0x1a 0x03 0x1a 0x1d 0x1a 0x1e 0x1a 0x1f 0x1a 0x20>;
			reset-names = "sata_rst\0usb0_crst\0usb1_crst\0usb0_hibrst\0usb1_hibrst\0usb0_apbrst\0usb1_apbrst\0dp_rst\0gem0_rst\0gem1_rst\0gem2_rst\0gem3_rst";
			phandle = <0x87>;

			lane0 {
				#phy-cells = <0x04>;
				phandle = <0x88>;
			};

			lane1 {
				#phy-cells = <0x04>;
				phandle = <0x22>;
			};

			lane2 {
				#phy-cells = <0x04>;
				phandle = <0x20>;
			};

			lane3 {
				#phy-cells = <0x04>;
				phandle = <0x1b>;
			};
		};

		ahci@fd0c0000 {
			compatible = "ceva,ahci-1v84";
			status = "okay";
			reg = <0x00 0xfd0c0000 0x00 0x2000>;
			interrupt-parent = <0x04>;
			interrupts = <0x00 0x85 0x04>;
			power-domains = <0x0c 0x1c>;
			#stream-id-cells = <0x04>;
			clocks = <0x03 0x16>;
			ceva,p0-cominit-params = <0x18401828>;
			ceva,p0-comwake-params = <0x614080e>;
			ceva,p0-burst-params = <0x13084a06>;
			ceva,p0-retry-params = <0x96a43ffc>;
			ceva,p1-cominit-params = <0x18401828>;
			ceva,p1-comwake-params = <0x614080e>;
			ceva,p1-burst-params = <0x13084a06>;
			ceva,p1-retry-params = <0x96a43ffc>;
			phy-names = "sata-phy";
			phys = <0x1b 0x01 0x01 0x01 0x7735940>;
			xlnx,tz-nonsecure-sata0 = <0x00>;
			xlnx,tz-nonsecure-sata1 = <0x00>;
			phandle = <0x89>;
		};

		mmc@ff160000 {
			u-boot,dm-pre-reloc;
			compatible = "xlnx,zynqmp-8.9a\0arasan,sdhci-8.9a";
			status = "disabled";
			interrupt-parent = <0x04>;
			interrupts = <0x00 0x30 0x04>;
			reg = <0x00 0xff160000 0x00 0x1000>;
			clock-names = "clk_xin\0clk_ahb";
			xlnx,device_id = <0x00>;
			#stream-id-cells = <0x01>;
			iommus = <0x0e 0x870>;
			power-domains = <0x0c 0x27>;
			nvmem-cells = <0x19>;
			nvmem-cell-names = "soc_revision";
			#clock-cells = <0x01>;
			clock-output-names = "clk_out_sd0\0clk_in_sd0";
			clocks = <0x03 0x36 0x03 0x1f>;
			phandle = <0x8a>;
		};

		mmc@ff170000 {
			u-boot,dm-pre-reloc;
			compatible = "xlnx,zynqmp-8.9a\0arasan,sdhci-8.9a";
			status = "okay";
			interrupt-parent = <0x04>;
			interrupts = <0x00 0x31 0x04>;
			reg = <0x00 0xff170000 0x00 0x1000>;
			clock-names = "clk_xin\0clk_ahb";
			xlnx,device_id = <0x01>;
			#stream-id-cells = <0x01>;
			iommus = <0x0e 0x871>;
			power-domains = <0x0c 0x28>;
			nvmem-cells = <0x19>;
			nvmem-cell-names = "soc_revision";
			#clock-cells = <0x01>;
			clock-output-names = "clk_out_sd1\0clk_in_sd1";
			clocks = <0x03 0x37 0x03 0x1f>;
			pinctrl-names = "default";
			pinctrl-0 = <0x1c>;
			no-1-8-v;
			clock-frequency = <0xb2cbcae>;
			xlnx,mio_bank = <0x01>;
			phandle = <0x8b>;
		};

		spi@ff040000 {
			compatible = "cdns,spi-r1p6";
			status = "disabled";
			interrupt-parent = <0x04>;
			interrupts = <0x00 0x13 0x04>;
			reg = <0x00 0xff040000 0x00 0x1000>;
			clock-names = "ref_clk\0pclk";
			#address-cells = <0x01>;
			#size-cells = <0x00>;
			power-domains = <0x0c 0x23>;
			clocks = <0x03 0x3a 0x03 0x1f>;
			phandle = <0x8c>;
		};

		spi@ff050000 {
			compatible = "cdns,spi-r1p6";
			status = "disabled";
			interrupt-parent = <0x04>;
			interrupts = <0x00 0x14 0x04>;
			reg = <0x00 0xff050000 0x00 0x1000>;
			clock-names = "ref_clk\0pclk";
			#address-cells = <0x01>;
			#size-cells = <0x00>;
			power-domains = <0x0c 0x24>;
			clocks = <0x03 0x3b 0x03 0x1f>;
			phandle = <0x8d>;
		};

		timer@ff110000 {
			compatible = "cdns,ttc";
			status = "disabled";
			interrupt-parent = <0x04>;
			interrupts = <0x00 0x24 0x04 0x00 0x25 0x04 0x00 0x26 0x04>;
			reg = <0x00 0xff110000 0x00 0x1000>;
			timer-width = <0x20>;
			power-domains = <0x0c 0x18>;
			clocks = <0x03 0x1f>;
			phandle = <0x8e>;
		};

		timer@ff120000 {
			compatible = "cdns,ttc";
			status = "disabled";
			interrupt-parent = <0x04>;
			interrupts = <0x00 0x27 0x04 0x00 0x28 0x04 0x00 0x29 0x04>;
			reg = <0x00 0xff120000 0x00 0x1000>;
			timer-width = <0x20>;
			power-domains = <0x0c 0x19>;
			clocks = <0x03 0x1f>;
			phandle = <0x8f>;
		};

		timer@ff130000 {
			compatible = "cdns,ttc";
			status = "disabled";
			interrupt-parent = <0x04>;
			interrupts = <0x00 0x2a 0x04 0x00 0x2b 0x04 0x00 0x2c 0x04>;
			reg = <0x00 0xff130000 0x00 0x1000>;
			timer-width = <0x20>;
			power-domains = <0x0c 0x1a>;
			clocks = <0x03 0x1f>;
			phandle = <0x90>;
		};

		timer@ff140000 {
			compatible = "cdns,ttc";
			status = "disabled";
			interrupt-parent = <0x04>;
			interrupts = <0x00 0x2d 0x04 0x00 0x2e 0x04 0x00 0x2f 0x04>;
			reg = <0x00 0xff140000 0x00 0x1000>;
			timer-width = <0x20>;
			power-domains = <0x0c 0x1b>;
			clocks = <0x03 0x1f>;
			phandle = <0x91>;
		};

		serial@ff000000 {
			u-boot,dm-pre-reloc;
			compatible = "cdns,uart-r1p12\0xlnx,xuartps";
			status = "okay";
			interrupt-parent = <0x04>;
			interrupts = <0x00 0x15 0x04>;
			reg = <0x00 0xff000000 0x00 0x1000>;
			clock-names = "uart_clk\0pclk";
			power-domains = <0x0c 0x21>;
			clocks = <0x03 0x38 0x03 0x1f>;
			pinctrl-names = "default";
			pinctrl-0 = <0x1d>;
			cts-override;
			device_type = "serial";
			port-number = <0x00>;
			phandle = <0x92>;
		};

		serial@ff010000 {
			u-boot,dm-pre-reloc;
			compatible = "cdns,uart-r1p12\0xlnx,xuartps";
			status = "okay";
			interrupt-parent = <0x04>;
			interrupts = <0x00 0x16 0x04>;
			reg = <0x00 0xff010000 0x00 0x1000>;
			clock-names = "uart_clk\0pclk";
			power-domains = <0x0c 0x22>;
			clocks = <0x03 0x39 0x03 0x1f>;
			pinctrl-names = "default";
			pinctrl-0 = <0x1e>;
			cts-override;
			device_type = "serial";
			port-number = <0x01>;
			phandle = <0x93>;
		};

		usb0@ff9d0000 {
			#address-cells = <0x02>;
			#size-cells = <0x02>;
			status = "okay";
			compatible = "xlnx,zynqmp-dwc3";
			reg = <0x00 0xff9d0000 0x00 0x100>;
			clock-names = "bus_clk\0ref_clk";
			power-domains = <0x0c 0x16>;
			ranges;
			nvmem-cells = <0x19>;
			nvmem-cell-names = "soc_revision";
			clocks = <0x03 0x20 0x03 0x22>;
			pinctrl-names = "default";
			pinctrl-0 = <0x1f>;
			xlnx,tz-nonsecure = <0x01>;
			xlnx,usb-polarity = <0x00>;
			xlnx,usb-reset-mode = <0x00>;
			phandle = <0x94>;

			dwc3@fe200000 {
				compatible = "snps,dwc3";
				status = "okay";
				reg = <0x00 0xfe200000 0x00 0x40000>;
				interrupt-parent = <0x04>;
				interrupt-names = "dwc_usb3\0otg\0hiber";
				interrupts = <0x00 0x41 0x04 0x00 0x45 0x04 0x00 0x4b 0x04>;
				#stream-id-cells = <0x01>;
				iommus = <0x0e 0x860>;
				snps,quirk-frame-length-adjustment = <0x20>;
				snps,refclk_fladj;
				snps,enable_guctl1_resume_quirk;
				snps,enable_guctl1_ipd_quirk;
				snps,xhci-stream-quirk;
				dr_mode = "host";
				snps,usb3_lpm_capable;
				phy-names = "usb3-phy";
				phys = <0x20 0x04 0x00 0x02 0x18cba80>;
				maximum-speed = "super-speed";
				phandle = <0x95>;
			};
		};

		usb1@ff9e0000 {
			#address-cells = <0x02>;
			#size-cells = <0x02>;
			status = "disabled";
			compatible = "xlnx,zynqmp-dwc3";
			reg = <0x00 0xff9e0000 0x00 0x100>;
			clock-names = "bus_clk\0ref_clk";
			power-domains = <0x0c 0x17>;
			ranges;
			nvmem-cells = <0x19>;
			nvmem-cell-names = "soc_revision";
			clocks = <0x03 0x21 0x03 0x22>;
			phandle = <0x96>;

			dwc3@fe300000 {
				compatible = "snps,dwc3";
				status = "disabled";
				reg = <0x00 0xfe300000 0x00 0x40000>;
				interrupt-parent = <0x04>;
				interrupt-names = "dwc_usb3\0otg\0hiber";
				interrupts = <0x00 0x46 0x04 0x00 0x4a 0x04 0x00 0x4c 0x04>;
				#stream-id-cells = <0x01>;
				iommus = <0x0e 0x861>;
				snps,quirk-frame-length-adjustment = <0x20>;
				snps,refclk_fladj;
				snps,enable_guctl1_resume_quirk;
				snps,enable_guctl1_ipd_quirk;
				snps,xhci-stream-quirk;
				phandle = <0x97>;
			};
		};

		watchdog@fd4d0000 {
			compatible = "cdns,wdt-r1p2";
			status = "okay";
			interrupt-parent = <0x04>;
			interrupts = <0x00 0x71 0x01>;
			reg = <0x00 0xfd4d0000 0x00 0x1000>;
			timeout-sec = <0x3c>;
			reset-on-timeout;
			clocks = <0x03 0x4b>;
			phandle = <0x98>;
		};

		watchdog@ff150000 {
			compatible = "cdns,wdt-r1p2";
			status = "okay";
			interrupt-parent = <0x04>;
			interrupts = <0x00 0x34 0x01>;
			reg = <0x00 0xff150000 0x00 0x1000>;
			timeout-sec = <0x0a>;
			clocks = <0x03 0x70>;
			phandle = <0x99>;
		};

		ams@ffa50000 {
			compatible = "xlnx,zynqmp-ams";
			status = "okay";
			interrupt-parent = <0x04>;
			interrupts = <0x00 0x38 0x04>;
			interrupt-names = "ams-irq";
			reg = <0x00 0xffa50000 0x00 0x800>;
			reg-names = "ams-base";
			#address-cells = <0x02>;
			#size-cells = <0x02>;
			#io-channel-cells = <0x01>;
			ranges;
			clocks = <0x03 0x46>;
			phandle = <0x9a>;

			ams_ps@ffa50800 {
				compatible = "xlnx,zynqmp-ams-ps";
				status = "okay";
				reg = <0x00 0xffa50800 0x00 0x400>;
				phandle = <0x9b>;
			};

			ams_pl@ffa50c00 {
				compatible = "xlnx,zynqmp-ams-pl";
				status = "okay";
				reg = <0x00 0xffa50c00 0x00 0x400>;
				phandle = <0x9c>;
			};
		};

		dma@fd4c0000 {
			compatible = "xlnx,dpdma";
			status = "okay";
			reg = <0x00 0xfd4c0000 0x00 0x1000>;
			interrupts = <0x00 0x7a 0x04>;
			interrupt-parent = <0x04>;
			clock-names = "axi_clk";
			power-domains = <0x0c 0x29>;
			dma-channels = <0x06>;
			#dma-cells = <0x01>;
			clocks = <0x03 0x14>;
			phandle = <0x23>;

			dma-video0channel {
				compatible = "xlnx,video0";
			};

			dma-video1channel {
				compatible = "xlnx,video1";
			};

			dma-video2channel {
				compatible = "xlnx,video2";
			};

			dma-graphicschannel {
				compatible = "xlnx,graphics";
			};

			dma-audio0channel {
				compatible = "xlnx,audio0";
			};

			dma-audio1channel {
				compatible = "xlnx,audio1";
			};
		};

		zynqmp-display@fd4a0000 {
			compatible = "xlnx,zynqmp-dpsub-1.7";
			status = "okay";
			reg = <0x00 0xfd4a0000 0x00 0x1000 0x00 0xfd4aa000 0x00 0x1000 0x00 0xfd4ab000 0x00 0x1000 0x00 0xfd4ac000 0x00 0x1000>;
			reg-names = "dp\0blend\0av_buf\0aud";
			interrupts = <0x00 0x77 0x04>;
			interrupt-parent = <0x04>;
			clock-names = "dp_apb_clk\0dp_aud_clk\0dp_vtc_pixel_clk_in";
			power-domains = <0x0c 0x29>;
			clocks = <0x21 0x03 0x11 0x03 0x10>;
			phy-names = "dp-phy0";
			phys = <0x22 0x06 0x00 0x03 0x19bfcc0>;
			xlnx,max-lanes = <0x01>;
			phandle = <0x9d>;

			vid-layer {
				dma-names = "vid0\0vid1\0vid2";
				dmas = <0x23 0x00 0x23 0x01 0x23 0x02>;
			};

			gfx-layer {
				dma-names = "gfx0";
				dmas = <0x23 0x03>;
			};

			i2c-bus {
			};

			zynqmp_dp_snd_codec0 {
				compatible = "xlnx,dp-snd-codec";
				clock-names = "aud_clk";
				clocks = <0x03 0x11>;
				status = "okay";
				phandle = <0x26>;
			};

			zynqmp_dp_snd_pcm0 {
				compatible = "xlnx,dp-snd-pcm";
				dmas = <0x23 0x04>;
				dma-names = "tx";
				status = "okay";
				phandle = <0x24>;
			};

			zynqmp_dp_snd_pcm1 {
				compatible = "xlnx,dp-snd-pcm";
				dmas = <0x23 0x05>;
				dma-names = "tx";
				status = "okay";
				phandle = <0x25>;
			};

			zynqmp_dp_snd_card {
				compatible = "xlnx,dp-snd-card";
				xlnx,dp-snd-pcm = <0x24 0x25>;
				xlnx,dp-snd-codec = <0x26>;
				status = "okay";
				phandle = <0x9e>;
			};
		};
	};

	fclk0 {
		status = "okay";
		compatible = "xlnx,fclk";
		clocks = <0x03 0x47>;
		phandle = <0x9f>;
	};

	fclk1 {
		status = "okay";
		compatible = "xlnx,fclk";
		clocks = <0x03 0x48>;
		phandle = <0xa0>;
	};

	fclk2 {
		status = "okay";
		compatible = "xlnx,fclk";
		clocks = <0x03 0x49>;
		phandle = <0xa1>;
	};

	fclk3 {
		status = "okay";
		compatible = "xlnx,fclk";
		clocks = <0x03 0x4a>;
		phandle = <0xa2>;
	};

	pss_ref_clk {
		u-boot,dm-pre-reloc;
		compatible = "fixed-clock";
		#clock-cells = <0x00>;
		clock-frequency = <0x1fc9350>;
		phandle = <0x06>;
	};

	video_clk {
		u-boot,dm-pre-reloc;
		compatible = "fixed-clock";
		#clock-cells = <0x00>;
		clock-frequency = <0x19bfcc0>;
		phandle = <0x07>;
	};

	pss_alt_ref_clk {
		u-boot,dm-pre-reloc;
		compatible = "fixed-clock";
		#clock-cells = <0x00>;
		clock-frequency = <0x00>;
		phandle = <0x08>;
	};

	gt_crx_ref_clk {
		u-boot,dm-pre-reloc;
		compatible = "fixed-clock";
		#clock-cells = <0x00>;
		clock-frequency = <0x66ff300>;
		phandle = <0x0a>;
	};

	aux_ref_clk {
		u-boot,dm-pre-reloc;
		compatible = "fixed-clock";
		#clock-cells = <0x00>;
		clock-frequency = <0x19bfcc0>;
		phandle = <0x09>;
	};

	dp_aclk {
		compatible = "fixed-clock";
		#clock-cells = <0x00>;
		clock-frequency = <0x5f5e100>;
		clock-accuracy = <0x64>;
		phandle = <0x21>;
	};

	gpio-keys {
		compatible = "gpio-keys";
		#address-cells = <0x01>;
		#size-cells = <0x00>;
		autorepeat;

		sw19 {
			label = "sw19";
			gpios = <0x14 0x16 0x00>;
			linux,code = <0x6c>;
			wakeup-source;
			autorepeat;
		};
	};

	leds {
		compatible = "gpio-leds";

		heartbeat-led {
			label = "heartbeat";
			gpios = <0x14 0x17 0x00>;
			linux,default-trigger = "heartbeat";
		};
	};

	chosen {
		xlnx,eeprom = "/amba/i2c@ff030000/i2c-mux@74/i2c@0/eeprom@54";
		bootargs = " earlycon console=ttyPS0,115200 clk_ignore_unused root=/dev/ram0 rw";
		stdout-path = "serial0:115200n8";
	};

	ina226-u76 {
		compatible = "iio-hwmon";
		io-channels = <0x27 0x00 0x27 0x01 0x27 0x02 0x27 0x03>;
	};

	ina226-u77 {
		compatible = "iio-hwmon";
		io-channels = <0x28 0x00 0x28 0x01 0x28 0x02 0x28 0x03>;
	};

	ina226-u78 {
		compatible = "iio-hwmon";
		io-channels = <0x29 0x00 0x29 0x01 0x29 0x02 0x29 0x03>;
	};

	ina226-u87 {
		compatible = "iio-hwmon";
		io-channels = <0x2a 0x00 0x2a 0x01 0x2a 0x02 0x2a 0x03>;
	};

	ina226-u85 {
		compatible = "iio-hwmon";
		io-channels = <0x2b 0x00 0x2b 0x01 0x2b 0x02 0x2b 0x03>;
	};

	ina226-u86 {
		compatible = "iio-hwmon";
		io-channels = <0x2c 0x00 0x2c 0x01 0x2c 0x02 0x2c 0x03>;
	};

	ina226-u93 {
		compatible = "iio-hwmon";
		io-channels = <0x2d 0x00 0x2d 0x01 0x2d 0x02 0x2d 0x03>;
	};

	ina226-u88 {
		compatible = "iio-hwmon";
		io-channels = <0x2e 0x00 0x2e 0x01 0x2e 0x02 0x2e 0x03>;
	};

	ina226-u15 {
		compatible = "iio-hwmon";
		io-channels = <0x2f 0x00 0x2f 0x01 0x2f 0x02 0x2f 0x03>;
	};

	ina226-u92 {
		compatible = "iio-hwmon";
		io-channels = <0x30 0x00 0x30 0x01 0x30 0x02 0x30 0x03>;
	};

	ina226-u79 {
		compatible = "iio-hwmon";
		io-channels = <0x31 0x00 0x31 0x01 0x31 0x02 0x31 0x03>;
	};

	ina226-u81 {
		compatible = "iio-hwmon";
		io-channels = <0x32 0x00 0x32 0x01 0x32 0x02 0x32 0x03>;
	};

	ina226-u80 {
		compatible = "iio-hwmon";
		io-channels = <0x33 0x00 0x33 0x01 0x33 0x02 0x33 0x03>;
	};

	ina226-u84 {
		compatible = "iio-hwmon";
		io-channels = <0x34 0x00 0x34 0x01 0x34 0x02 0x34 0x03>;
	};

	ina226-u16 {
		compatible = "iio-hwmon";
		io-channels = <0x35 0x00 0x35 0x01 0x35 0x02 0x35 0x03>;
	};

	ina226-u65 {
		compatible = "iio-hwmon";
		io-channels = <0x36 0x00 0x36 0x01 0x36 0x02 0x36 0x03>;
	};

	ina226-u74 {
		compatible = "iio-hwmon";
		io-channels = <0x37 0x00 0x37 0x01 0x37 0x02 0x37 0x03>;
	};

	ina226-u75 {
		compatible = "iio-hwmon";
		io-channels = <0x38 0x00 0x38 0x01 0x38 0x02 0x38 0x03>;
	};

	amba_pl@0 {
		#address-cells = <0x02>;
		#size-cells = <0x02>;
		compatible = "simple-bus";
		ranges;
		phandle = <0xa3>;

		dma@a0000000 {
			#dma-cells = <0x01>;
			clock-names = "s_axi_lite_aclk\0m_axi_sg_aclk\0m_axi_mm2s_aclk\0m_axi_s2mm_aclk";
			clocks = <0x03 0x47 0x03 0x47 0x39 0x39>;
			compatible = "xlnx,eth-dma";
			interrupt-names = "mm2s_introut\0s2mm_introut";
			interrupt-parent = <0x04>;
			interrupts = <0x00 0x59 0x04 0x00 0x5a 0x04>;
			reg = <0x00 0xa0000000 0x00 0x10000>;
			xlnx,addrwidth = [20];
			xlnx,include-dre;
			xlnx,num-queues = [00 01];
			phandle = <0x3a>;
		};

		misc_clk_0 {
			#clock-cells = <0x00>;
			clock-frequency = <0x9502f90>;
			compatible = "fixed-clock";
			phandle = <0x39>;
		};

		gpio@a0010000 {
			#gpio-cells = <0x03>;
			clock-names = "s_axi_aclk";
			clocks = <0x03 0x47>;
			compatible = "xlnx,axi-gpio-2.0\0xlnx,xps-gpio-1.00.a";
			gpio-controller;
			reg = <0x00 0xa0010000 0x00 0x10000>;
			xlnx,all-inputs = <0x00>;
			xlnx,all-inputs-2 = <0x00>;
			xlnx,all-outputs = <0x01>;
			xlnx,all-outputs-2 = <0x00>;
			xlnx,dout-default = <0x00>;
			xlnx,dout-default-2 = <0x00>;
			xlnx,gpio-width = <0x01>;
			xlnx,gpio2-width = <0x20>;
			xlnx,interrupt-present = <0x00>;
			xlnx,is-dual = <0x00>;
			xlnx,tri-default = <0xffffffff>;
			xlnx,tri-default-2 = <0xffffffff>;
			phandle = <0xa4>;
		};

		ethernet@a0040000 {
			axistream-connected = <0x3a>;
			axistream-control-connected = <0x3a>;
			clock-frequency = <0x5f5e100>;
			clock-names = "rx_core_clk\0dclk\0s_axi_aclk\0s_axi_lite_aclk\0m_axi_sg_aclk\0m_axi_mm2s_aclk\0m_axi_s2mm_aclk";
			clocks = <0x39 0x03 0x47 0x03 0x47 0x03 0x47 0x03 0x47 0x39 0x39>;
			compatible = "xlnx,xxv-ethernet-3.2\0xlnx,xxv-ethernet-1.0";
			device_type = "network";
			local-mac-address = [00 0a 35 00 00 01];
			phy-mode = "base-r";
			reg = <0x00 0xa0040000 0x00 0x40000>;
			xlnx = <0x00>;
			xlnx,add-gt-cntrl-sts-ports = <0x00>;
			xlnx,anlt-clk-in-mhz = <0x64>;
			xlnx,axis-tdata-width = <0x40>;
			xlnx,axis-tkeep-width = <0x07>;
			xlnx,base-r-kr = "BASE-R";
			xlnx,clocking = "Asynchronous";
			xlnx,cmac-core-select = "CMACE4_X0Y0";
			xlnx,core = "Ethernet MAC+PCS/PMA 64-bit";
			xlnx,data-path-interface = "AXI Stream";
			xlnx,enable-datapath-parity = <0x00>;
			xlnx,enable-pipeline-reg = <0x00>;
			xlnx,enable-preemption = <0x00>;
			xlnx,enable-preemption-fifo = <0x00>;
			xlnx,enable-rx-flow-control-logic = <0x00>;
			xlnx,enable-time-stamping = <0x00>;
			xlnx,enable-tx-flow-control-logic = <0x00>;
			xlnx,enable-vlane-adjust-mode = <0x00>;
			xlnx,family-chk = "zynquplus";
			xlnx,fast-sim-mode = <0x00>;
			xlnx,gt-diffctrl-width = <0x04>;
			xlnx,gt-drp-clk = "100.00";
			xlnx,gt-group-select = "Quad X0Y0";
			xlnx,gt-location = <0x01>;
			xlnx,gt-ref-clk-freq = "156.25";
			xlnx,gt-type = "GTH";
			xlnx,gtm-group-select = "NA";
			xlnx,include-auto-neg-lt-logic = "None";
			xlnx,include-axi4-interface = <0x01>;
			xlnx,include-dre;
			xlnx,include-fec-logic = <0x00>;
			xlnx,include-hybrid-cmac-rsfec-logic = <0x00>;
			xlnx,include-rsfec-logic = <0x00>;
			xlnx,include-shared-logic = <0x01>;
			xlnx,include-statistics-counters = <0x01>;
			xlnx,include-user-fifo = <0x01>;
			xlnx,ins-loss-nyq = <0x1e>;
			xlnx,lane1-gt-loc = "X1Y14";
			xlnx,lane2-gt-loc = "NA";
			xlnx,lane3-gt-loc = "NA";
			xlnx,lane4-gt-loc = "NA";
			xlnx,line-rate = <0x0a>;
			xlnx,mii-ctrl-width = <0x04>;
			xlnx,mii-data-width = <0x20>;
			xlnx,num-of-cores = <0x01>;
			xlnx,ptp-clocking-mode = <0x00>;
			xlnx,ptp-operation-mode = <0x02>;
			xlnx,runtime-switch = <0x00>;
			xlnx,rx-eq-mode = "AUTO";
			xlnx,rxmem = <0x40000>;
			xlnx,statistics-regs-type = <0x00>;
			xlnx,switch-1-10-25g = <0x00>;
			xlnx,tx-latency-adjust = <0x00>;
			xlnx,tx-total-bytes-width = <0x04>;
			xlnx,xgmii-interface = <0x01>;
			phandle = <0xa5>;

			mdio {
				#address-cells = <0x01>;
				#size-cells = <0x00>;
				phandle = <0xa6>;
			};
		};
	};

	aliases {
		ethernet0 = "/amba/ethernet@ff0e0000";
		ethernet1 = "/amba_pl@0/ethernet@a0040000";
		i2c0 = "/amba/i2c@ff020000";
		i2c1 = "/amba/i2c@ff030000";
		serial0 = "/amba/serial@ff000000";
		serial1 = "/amba/serial@ff010000";
		spi0 = "/amba/spi@ff0f0000";
	};

	memory {
		device_type = "memory";
		reg = <0x00 0x00 0x00 0x7ff00000 0x08 0x00 0x00 0x80000000>;
	};

	__symbols__ {
		cpu0 = "/cpus/cpu@0";
		cpu1 = "/cpus/cpu@1";
		cpu2 = "/cpus/cpu@2";
		cpu3 = "/cpus/cpu@3";
		CPU_SLEEP_0 = "/cpus/idle-states/cpu-sleep-0";
		cpu_opp_table = "/cpu-opp-table";
		ipi_mailbox_pmu1 = "/zynqmp_ipi/mailbox@ff990400";
		dcc = "/dcc";
		zynqmp_firmware = "/firmware/zynqmp-firmware";
		zynqmp_pcap = "/firmware/zynqmp-firmware/pcap";
		zynqmp_power = "/firmware/zynqmp-firmware/zynqmp-power";
		zynqmp_reset = "/firmware/zynqmp-firmware/reset-controller";
		pinctrl0 = "/firmware/zynqmp-firmware/pinctrl";
		pinctrl_i2c0_default = "/firmware/zynqmp-firmware/pinctrl/i2c0-default";
		pinctrl_i2c0_gpio = "/firmware/zynqmp-firmware/pinctrl/i2c0-gpio";
		pinctrl_i2c1_default = "/firmware/zynqmp-firmware/pinctrl/i2c1-default";
		pinctrl_i2c1_gpio = "/firmware/zynqmp-firmware/pinctrl/i2c1-gpio";
		pinctrl_uart0_default = "/firmware/zynqmp-firmware/pinctrl/uart0-default";
		pinctrl_uart1_default = "/firmware/zynqmp-firmware/pinctrl/uart1-default";
		pinctrl_usb0_default = "/firmware/zynqmp-firmware/pinctrl/usb0-default";
		pinctrl_gem3_default = "/firmware/zynqmp-firmware/pinctrl/gem3-default";
		pinctrl_can1_default = "/firmware/zynqmp-firmware/pinctrl/can1-default";
		pinctrl_sdhci1_default = "/firmware/zynqmp-firmware/pinctrl/sdhci1-default";
		pinctrl_gpio_default = "/firmware/zynqmp-firmware/pinctrl/gpio-default";
		zynqmp_clk = "/firmware/zynqmp-firmware/clock-controller";
		fpga_full = "/fpga-full";
		soc_revision = "/nvmem_firmware/soc_revision@0";
		efuse_dna = "/nvmem_firmware/efuse_dna@c";
		efuse_usr0 = "/nvmem_firmware/efuse_usr0@20";
		efuse_usr1 = "/nvmem_firmware/efuse_usr1@24";
		efuse_usr2 = "/nvmem_firmware/efuse_usr2@28";
		efuse_usr3 = "/nvmem_firmware/efuse_usr3@2c";
		efuse_usr4 = "/nvmem_firmware/efuse_usr4@30";
		efuse_usr5 = "/nvmem_firmware/efuse_usr5@34";
		efuse_usr6 = "/nvmem_firmware/efuse_usr6@38";
		efuse_usr7 = "/nvmem_firmware/efuse_usr7@3c";
		efuse_miscusr = "/nvmem_firmware/efuse_miscusr@40";
		efuse_chash = "/nvmem_firmware/efuse_chash@50";
		efuse_pufmisc = "/nvmem_firmware/efuse_pufmisc@54";
		efuse_sec = "/nvmem_firmware/efuse_sec@58";
		efuse_spkid = "/nvmem_firmware/efuse_spkid@5c";
		efuse_ppk0hash = "/nvmem_firmware/efuse_ppk0hash@a0";
		efuse_ppk1hash = "/nvmem_firmware/efuse_ppk1hash@d0";
		xlnx_rsa = "/zynqmp_rsa";
		xlnx_keccak_384 = "/sha384";
		xlnx_aes = "/zynqmp_aes";
		amba_apu = "/amba-apu@0";
		gic = "/amba-apu@0/interrupt-controller@f9010000";
		smmu = "/smmu@fd800000";
		amba = "/amba";
		can0 = "/amba/can@ff060000";
		can1 = "/amba/can@ff070000";
		cci = "/amba/cci@fd6e0000";
		fpd_dma_chan1 = "/amba/dma@fd500000";
		fpd_dma_chan2 = "/amba/dma@fd510000";
		fpd_dma_chan3 = "/amba/dma@fd520000";
		fpd_dma_chan4 = "/amba/dma@fd530000";
		fpd_dma_chan5 = "/amba/dma@fd540000";
		fpd_dma_chan6 = "/amba/dma@fd550000";
		fpd_dma_chan7 = "/amba/dma@fd560000";
		fpd_dma_chan8 = "/amba/dma@fd570000";
		gpu = "/amba/gpu@fd4b0000";
		lpd_dma_chan1 = "/amba/dma@ffa80000";
		lpd_dma_chan2 = "/amba/dma@ffa90000";
		lpd_dma_chan3 = "/amba/dma@ffaa0000";
		lpd_dma_chan4 = "/amba/dma@ffab0000";
		lpd_dma_chan5 = "/amba/dma@ffac0000";
		lpd_dma_chan6 = "/amba/dma@ffad0000";
		lpd_dma_chan7 = "/amba/dma@ffae0000";
		lpd_dma_chan8 = "/amba/dma@ffaf0000";
		mc = "/amba/memory-controller@fd070000";
		nand0 = "/amba/nand@ff100000";
		gem0 = "/amba/ethernet@ff0b0000";
		gem1 = "/amba/ethernet@ff0c0000";
		gem2 = "/amba/ethernet@ff0d0000";
		gem3 = "/amba/ethernet@ff0e0000";
		phyc = "/amba/ethernet@ff0e0000/ethernet-phy@c";
		gpio = "/amba/gpio@ff0a0000";
		i2c0 = "/amba/i2c@ff020000";
		tca6416_u97 = "/amba/i2c@ff020000/gpio@20";
		tca6416_u61 = "/amba/i2c@ff020000/gpio@21";
		u76 = "/amba/i2c@ff020000/i2c-mux@75/i2c@0/ina226@40";
		u77 = "/amba/i2c@ff020000/i2c-mux@75/i2c@0/ina226@41";
		u78 = "/amba/i2c@ff020000/i2c-mux@75/i2c@0/ina226@42";
		u87 = "/amba/i2c@ff020000/i2c-mux@75/i2c@0/ina226@43";
		u85 = "/amba/i2c@ff020000/i2c-mux@75/i2c@0/ina226@44";
		u86 = "/amba/i2c@ff020000/i2c-mux@75/i2c@0/ina226@45";
		u93 = "/amba/i2c@ff020000/i2c-mux@75/i2c@0/ina226@46";
		u88 = "/amba/i2c@ff020000/i2c-mux@75/i2c@0/ina226@47";
		u15 = "/amba/i2c@ff020000/i2c-mux@75/i2c@0/ina226@4a";
		u92 = "/amba/i2c@ff020000/i2c-mux@75/i2c@0/ina226@4b";
		u79 = "/amba/i2c@ff020000/i2c-mux@75/i2c@1/ina226@40";
		u81 = "/amba/i2c@ff020000/i2c-mux@75/i2c@1/ina226@41";
		u80 = "/amba/i2c@ff020000/i2c-mux@75/i2c@1/ina226@42";
		u84 = "/amba/i2c@ff020000/i2c-mux@75/i2c@1/ina226@43";
		u16 = "/amba/i2c@ff020000/i2c-mux@75/i2c@1/ina226@44";
		u65 = "/amba/i2c@ff020000/i2c-mux@75/i2c@1/ina226@45";
		u74 = "/amba/i2c@ff020000/i2c-mux@75/i2c@1/ina226@46";
		u75 = "/amba/i2c@ff020000/i2c-mux@75/i2c@1/ina226@47";
		i2c1 = "/amba/i2c@ff030000";
		eeprom = "/amba/i2c@ff030000/i2c-mux@74/i2c@0/eeprom@54";
		board_sn = "/amba/i2c@ff030000/i2c-mux@74/i2c@0/eeprom@54/board-sn@0";
		eth_mac = "/amba/i2c@ff030000/i2c-mux@74/i2c@0/eeprom@54/eth-mac@20";
		board_name = "/amba/i2c@ff030000/i2c-mux@74/i2c@0/eeprom@54/board-name@d0";
		board_revision = "/amba/i2c@ff030000/i2c-mux@74/i2c@0/eeprom@54/board-revision@e0";
		si5341 = "/amba/i2c@ff030000/i2c-mux@74/i2c@1/clock-generator@36";
		si570_1 = "/amba/i2c@ff030000/i2c-mux@74/i2c@2/clock-generator@5d";
		si570_2 = "/amba/i2c@ff030000/i2c-mux@74/i2c@3/clock-generator@5d";
		si5328 = "/amba/i2c@ff030000/i2c-mux@74/i2c@4/clock-generator@69";
		ocm = "/amba/memory-controller@ff960000";
		perf_monitor_ocm = "/amba/perf-monitor@ffa00000";
		perf_monitor_ddr = "/amba/perf-monitor@fd0b0000";
		perf_monitor_cci = "/amba/perf-monitor@fd490000";
		perf_monitor_lpd = "/amba/perf-monitor@ffa10000";
		pcie = "/amba/pcie@fd0e0000";
		pcie_intc = "/amba/pcie@fd0e0000/legacy-interrupt-controller";
		qspi = "/amba/spi@ff0f0000";
		flash0 = "/amba/spi@ff0f0000/flash@0";
		rtc = "/amba/rtc@ffa60000";
		serdes = "/amba/zynqmp_phy@fd400000";
		lane0 = "/amba/zynqmp_phy@fd400000/lane0";
		lane1 = "/amba/zynqmp_phy@fd400000/lane1";
		lane2 = "/amba/zynqmp_phy@fd400000/lane2";
		lane3 = "/amba/zynqmp_phy@fd400000/lane3";
		sata = "/amba/ahci@fd0c0000";
		sdhci0 = "/amba/mmc@ff160000";
		sdhci1 = "/amba/mmc@ff170000";
		spi0 = "/amba/spi@ff040000";
		spi1 = "/amba/spi@ff050000";
		ttc0 = "/amba/timer@ff110000";
		ttc1 = "/amba/timer@ff120000";
		ttc2 = "/amba/timer@ff130000";
		ttc3 = "/amba/timer@ff140000";
		uart0 = "/amba/serial@ff000000";
		uart1 = "/amba/serial@ff010000";
		usb0 = "/amba/usb0@ff9d0000";
		dwc3_0 = "/amba/usb0@ff9d0000/dwc3@fe200000";
		usb1 = "/amba/usb1@ff9e0000";
		dwc3_1 = "/amba/usb1@ff9e0000/dwc3@fe300000";
		watchdog0 = "/amba/watchdog@fd4d0000";
		lpd_watchdog = "/amba/watchdog@ff150000";
		xilinx_ams = "/amba/ams@ffa50000";
		ams_ps = "/amba/ams@ffa50000/ams_ps@ffa50800";
		ams_pl = "/amba/ams@ffa50000/ams_pl@ffa50c00";
		xlnx_dpdma = "/amba/dma@fd4c0000";
		zynqmp_dpsub = "/amba/zynqmp-display@fd4a0000";
		zynqmp_dp_snd_codec0 = "/amba/zynqmp-display@fd4a0000/zynqmp_dp_snd_codec0";
		zynqmp_dp_snd_pcm0 = "/amba/zynqmp-display@fd4a0000/zynqmp_dp_snd_pcm0";
		zynqmp_dp_snd_pcm1 = "/amba/zynqmp-display@fd4a0000/zynqmp_dp_snd_pcm1";
		zynqmp_dp_snd_card0 = "/amba/zynqmp-display@fd4a0000/zynqmp_dp_snd_card";
		fclk0 = "/fclk0";
		fclk1 = "/fclk1";
		fclk2 = "/fclk2";
		fclk3 = "/fclk3";
		pss_ref_clk = "/pss_ref_clk";
		video_clk = "/video_clk";
		pss_alt_ref_clk = "/pss_alt_ref_clk";
		gt_crx_ref_clk = "/gt_crx_ref_clk";
		aux_ref_clk = "/aux_ref_clk";
		dp_aclk = "/dp_aclk";
		amba_pl = "/amba_pl@0";
		axi_dma_0 = "/amba_pl@0/dma@a0000000";
		misc_clk_0 = "/amba_pl@0/misc_clk_0";
		axi_gpio_0 = "/amba_pl@0/gpio@a0010000";
		xxv_ethernet_0 = "/amba_pl@0/ethernet@a0040000";
		xxv_ethernet_0_mdio = "/amba_pl@0/ethernet@a0040000/mdio";
	};
};
